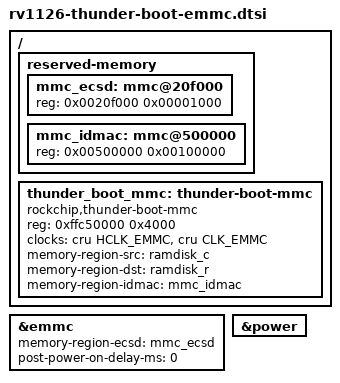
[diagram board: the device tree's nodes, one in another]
// SPDX-License-Identifier: (GPL-2.0+ OR MIT)
/*
 * Copyright (c) 2020 Rockchip Electronics Co., Ltd.
 */

#include "rv1126-thunder-boot.dtsi"

/ {
	reserved-memory {
		mmc_ecsd: mmc@20f000 {
			reg = <0x0020f000 0x00001000>;
		};

		mmc_idmac: mmc@500000 {
			reg = <0x00500000 0x00100000>;
		};
	};

	thunder_boot_mmc: thunder-boot-mmc {
		compatible = "rockchip,thunder-boot-mmc";
		reg = <0xffc50000 0x4000>;
		clocks = <&cru HCLK_EMMC>, <&cru CLK_EMMC>;
		clock-names = "biu", "ciu";
		memory-region-src = <&ramdisk_c>;
		memory-region-dst = <&ramdisk_r>;
		memory-region-idmac = <&mmc_idmac>;
	};
};

&emmc {
	/delete-property/ power-domains;
	memory-region-ecsd = <&mmc_ecsd>;
	post-power-on-delay-ms = <0>;
};

&power {
	/delete-node/ pd_nvm@RV1126_PD_NVM;
};
